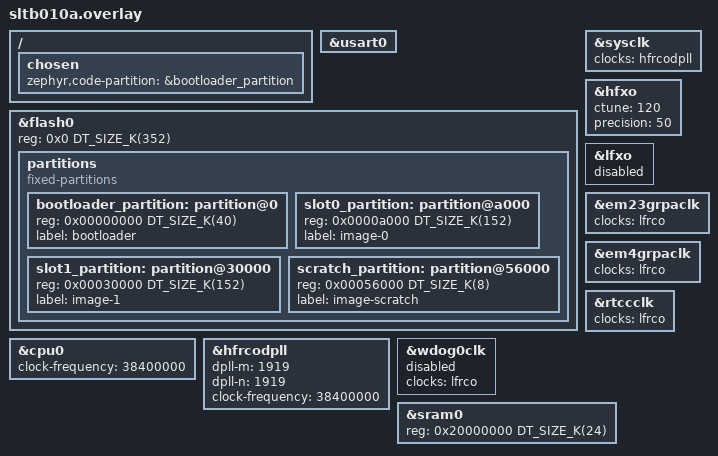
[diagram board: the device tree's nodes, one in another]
/ {
	chosen {
		zephyr,code-partition = &bootloader_partition;
	};
};

&usart0 {
	/delete-node/ mx25r8035f@0;
};

&flash0 {
	reg = <0x0 DT_SIZE_K(352)>;

	/delete-node/ partitions;

	partitions {
		compatible = "fixed-partitions";
		#address-cells = <1>;
		#size-cells = <1>;

		bootloader_partition: partition@0 {
			reg = <0x00000000 DT_SIZE_K(40)>;
			label = "bootloader";
		};

		slot0_partition: partition@a000 {
			reg = <0x0000a000 DT_SIZE_K(152)>;
			label = "image-0";
		};

		slot1_partition: partition@30000 {
			reg = <0x00030000 DT_SIZE_K(152)>;
			label = "image-1";
		};

		scratch_partition: partition@56000 {
			reg = <0x00056000 DT_SIZE_K(8)>;
			label = "image-scratch";
		};
	};
};

&cpu0 {
	clock-frequency = <38400000>;
};

&hfrcodpll {
	dpll-m = <1919>;
	dpll-n = <1919>;
	clock-frequency = <38400000>;
};

&sysclk {
	clocks = <&hfrcodpll>;
};

&hfxo {
	status = "okay";
	ctune = <120>;
	precision = <50>;
};

&lfxo {
	status = "disabled";
};

&em23grpaclk {
	clocks = <&lfrco>;
};

&em4grpaclk {
	clocks = <&lfrco>;
};

&rtccclk {
	clocks = <&lfrco>;
};

&wdog0clk {
	clocks = <&lfrco>;
	status = "disabled";
};

&sram0 {
	reg = <0x20000000 DT_SIZE_K(24)>;
};
